# cyt4dn register map
Vendor: Cypress Semiconductor; Series: cyt4dn; File version: 1.0
CPU: CM7 r0p1, little endian, MPU, FPU, VTOR, 3 interrupt priority bits
Registers are 32-bit, read-write, reset 0x0 unless marked. A register's access mark holds for its fields unless they carry their own. Offsets are from the block's base; [hi:lo] are bit positions; lines under a group give offsets from that group; {n}, {i} and the like mark numbered series; 'fields as' and 'values as' point back to an identical list; <NAME> marks a mode.

## SMIF0 (part 2 of 2) — SMIF subsystem (bridge + 2 core SMIFs, OR no bridge and 1 core SMIF)
Base 0x40400000
{0x20000+0x10000*i} CORE[{i}] (i=0..1) group — Serial Memory Interface
  0x00 CTL reset 0x500000 — Control
    [31] ENABLED — SMIF core enable: '0': Disabled. All non-retention registers are reset to their default value when this SMIF core is disabled. When this SMIF core is disabled, the XIP accesses produce AHB-Lite bus errors and AXI error responses. '1': Enabled. Notes: - Before disabling or resetting this SMIF core, SW should ensure that this SMIF core is NOT busy (STATUS.BUSY is '0'), otherwise illegal interface transfers may occur. - After CTL.ENABLED is set to 1 it takes up to 20 clk_if cycles until the memory interface registers are realeased from reset. - The DLL is powered up when CTL.ENABLED is set to 1. It takes 8us for the DLL to stabilize and lock to the freerunning PLL clock at which point STATUS.DLL_LOCKED and INTR.DLL_LOCK will be set. Wait another 4us beyond that before executing any transactions on the memory interface; the MDL and SDLs require that extra time after the lock indication to reach their final stable delay values.
      0=DISABLED (N/A); 1=ENABLED (N/A)
    [25] CLOCK_IF_SEL — Specifies the clock source for 'clk_if'. Must be 0 (clk_pll_normal) before entering DeepSleep; can be returned to 1 (clk_pll_direct) afterwards. '0': clk_pll_normal is used to create clk_if '1': clk_pll_direct is used to create clk_if
    [24] BLOCK — Specifies what happens for MMIO interface read accesses to an empty RX data FIFO or to a full TX format/data FIFO. This field is not used for test controller accesses.
      0=BUS_ERROR (0': Generate an AHB-Lite bus error. This option is useful when SW decides to use polling on STATUS.TR_BUSY to determine if a interface transfer is no longer busy (transfer is completed). This option adds SW complexity, but limits the number of AHB-Lite wait states (and limits ISR latency).); 1=WAIT_STATES (1': Introduce wait states. This setting potentially locks up the AHB-Lite infrastructure and may increase the CPU interrupt latency.This option is useful when SW performs TX/RX data FIFO accesses immediately after a command is setup using the TX format FIFO. This option has low SW complexity, but may result in a significant number of AHB-Lite wait states (and may increase ISR latency). This can be particularly true if ARB_MODE=1 and an MMIO access must wait a potentially long time behind a XIP access.)
    [23:22] SELECT_HOLD_DELAY — Specifies the duration between the last 'spi_clk_out' falling edge and 'spi_select_out[]' deactivating (going high) before considering any MDL delay due to CTL2.MDL_TAP_SEL. Add that delay to the below values, plus allow some margin for combinatorial variances between spi_select_out[] and spi_clk_out. i.e., if after adding the MDL delay the timing would barely meet the memory datasheet requirement then it is recommended to go to the next higher setting. These values apply for DDR mode, or SDR mode with CTL2.TX_SDR_EXTRA_SETUP=0. For SDR mode with CTL2.TX_SDR_EXTRA_SETUP=1 subtract 1 PLL clock cycle from these values. DDR or SDR mode is determined by the mode of the last phase of the transaction. '0': 1 memory interface clock cycle + CTL2.CLKOUT_DIV adjustment '1': 2 memory interface clock cycles + CTL2.CLKOUT_DIV adjustment '2': 3 memory interface clock cycles + CTL2.CLKOUT_DIV adjustment '3': 4 memory interface clock cycles + CTL2.CLKOUT_DIV adjustment For the following settings of CTL2.CLKOUT_DIV apply these adjustments to the above: 0 (DIV2): subtract 1 PLL clock cycle 1 (DIV4): no adjustment needed 2 (DIV8): add 2 PLL clock cycles 3 (DIV16): add 6 PLL clock cycles
    [21:20] SELECT_SETUP_DELAY — Specifies the duration between 'spi_select_out[]' activating (going low) to the first 'spi_clk_out' rising edge before considering any MDL delay due to CTL2.MDL_TAP_SEL. Subtract that delay from the below values, plus allow some margin for combinatorial variances between spi_select_out[] and spi_clk_out. i.e., if after subtracting the MDL delay the timing would barely meet the memory datasheet requirement then it is recommended to go to the next higher setting. These values apply for DDR mode, or SDR mode with CTL2.TX_SDR_EXTRA_SETUP=0. For SDR mode with CTL2.TX_SDR_EXTRA_SETUP=1 add 1 PLL clock cycle to these values. DDR or SDR mode is determined by the mode of the first phase of the transaction. '0': 2 PLL clock cycles '1': 2 PLL clock cycles + 1 memory interface clock cycles '2': 2 PLL clock cycles + 2 memory interface clock cycles '3': 2 PLL clock cycles + 3 memory interface clock cycles
    [18:16] DESELECT_DELAY — Specifies the minimum duration of SPI deselection ('spi_select_out[]' is high/'1') in between SPI transfers: '0': 1 memory interface clock cycle. '1': 2 memory interface clock cycles. '2': 3 memory interface clock cycles. '3': 4 memory interface clock cycles. '4': 5 memory interface clock cycles. '5': 6 memory interface clock cycles. '6': 7 memory interface clock cycles. '7': 8 memory interface clock cycles. During SPI deselection, 'spi_select_out[]' are '1'/inactive, 'spi_data_out[]' are '1' and 'spi_clk_out' is '0'/inactive.
    [0] XIP_MODE — Mode of operation. Note: this field should only be changed when the IP is disabled or when STATUS.BUSY is '0' and SW should not be executing from the XIP interface or MMIO interface.
      0=MMIO_MODE ('0': MMIO mode. Individual MMIO accesses to TX and RX FIFOs are used to generate a sequence of SPI transfers. This mode of operation allows for large flexibility in terms of the SPI transfers that can be generated.); 1=ARB_MODE (''1': Arbitration mode. Arbitrates XIP vs. MMIO accesses such that any ongoing, pending, or 'merged' transactions on XIP always take priority over any MMIO accesses to the device. However, if an MMIO access is in process it cannot be interrupted until it completes (as defined by sending the 'last command' via TX_CMD_MMIO_FIFO_WR). If MMIO accesses are not happening at all, though, then the XIP accesses endure no extra arbitration latency.)
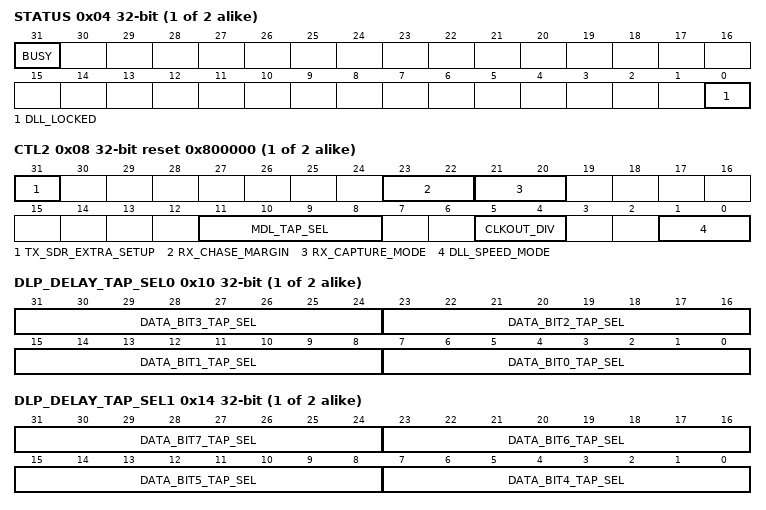
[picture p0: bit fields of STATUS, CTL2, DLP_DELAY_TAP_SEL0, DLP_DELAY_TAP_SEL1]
  0x04 STATUS ro reset not defined
    [31] BUSY — AHB Cache, AXI interface, cryptography, XIP, device interface, MPC (if present) initialization, or any other key logic busy in the IP: '0': not busy '1': busy When BUSY is '0', the IP can be safely disabled without: - the potential loss of transient write data. - the potential risk of aborting an inflight SPI device interface transfer. - disrupting MPC (if present) initialization When BUSY is '0', the mode of operation (ARB_MODE or MMIO_MODE) can be safely changed.
    [0] DLL_LOCKED — 0: DLL is not locked 1: DLL is locked Once the reference clock to the DLL is stable and the DLL is powered (CTL.ENABLED=1), the DLL should lock within 8us. The lock time will also be incurred when transitioning from DeepSleep to Active. Wait another 4us beyond the lock indication before executing any transactions on the memory interface; the MDL and SDLs require that extra time after the lock indication to reach their final stable delay values. If the DLL suddenly becomes unlocked then the TX interface will be held in reset to prevent any further transactions to the memory. The block should be disabled (CTL.ENABLED=0) to reset all other non-retention registers. Any data in the internal FIFOs will be lost. The DLL suddenly unlocking is considered an unusual event that would only occur if the reference clock to the DLL had a sudden change in frequency, which should only happen at the direction of SW. When transitioning to DeepSleep the DLL will naturally unlock. However, upon returning to Active all non-retention registers are reset and thus disabling the block to enact that reset is not necessary.
  0x08 CTL2 reset 0x800000 — Control 2
    [31] TX_SDR_EXTRA_SETUP — This field is only applicable in SDR transmit mode. 0: transmit data is launched nominally 1 PLL clock period ahead of the rising edge of the clock out to the memory 1: transmit data is launched nominally 2 PLL clock periods ahead of the rising edge of the clock out to the memory
    [23:22] RX_CHASE_MARGIN — Determines how long the design should wait after sending the last clock out to the memory interface before 'chase' clocks should be created internally to push remainder data in the interface pipeline into the RX FIFO. Lesser numbers allow for shorter deselect cycles between packets, but if the time is too short then the chase clocks will interfere with the normal capture clock from the last clock cycle from the memory interface (whether it is feedback or RWDS). So a proper balance must be struck. The default value is expected to work for all situations. Other values are there as a backup plan in case something more aggressive can be achieved or whether something even more conservative should be used.
    [21:20] RX_CAPTURE_MODE
    [11:8] MDL_TAP_SEL — Determines the relative amount of delay through the MDL for the reference clock in terms of the number of tap delays. There are 16 MDL taps that evenly divide the reference clock period into 16 delay steps. Setting 0 constitutes 1 tap delay, setting 1 constitutes 2 tap delays, etc., setting 15 constitutes 16 tap delays (which is effectively a full MDL reference clock period, which can be thought of as 'zero delay' since it aligns the posedges of the output to the input reference).
    [5:4] CLKOUT_DIV — The clock out to the memory is a divided version of the MDL clock out: 0: divide by 2 1: divide by 4 2: divide by 8 3: divide by 16
    [1:0] DLL_SPEED_MODE — Set according to the PLL clock frequency that feeds the DLL: 0: 160 to 180 MHz 1: >180 to 266 MHz 2: >266 to 333 MHz 3: >333 to 400 MHz
  0x10 DLP_DELAY_TAP_SEL0 ro reset not defined — DLP Delay Tap Select Register 0
    [31:24] DATA_BIT3_TAP_SEL — Delay line tap selection for the IP's spi_data[3] (note the mapping of spi_data to IO in DEVICE.CTL.DATA_SEL). See DATA_BIT0_TAP_SEL.
    [23:16] DATA_BIT2_TAP_SEL — Delay line tap selection for the IP's spi_data[2] (note the mapping of spi_data to IO in DEVICE.CTL.DATA_SEL). See DATA_BIT0_TAP_SEL.
    [15:8] DATA_BIT1_TAP_SEL — Delay line tap selection for the IP's spi_data[1] (note the mapping of spi_data to IO in DEVICE.CTL.DATA_SEL). See DATA_BIT0_TAP_SEL.
    [7:0] DATA_BIT0_TAP_SEL — DLP tap selection for the IP's spi_data[0] (note the mapping of spi_data to IO in DEVICE.CTL.DATA_SEL). In SDR mode: The upper 4 bits of this field are zero, while the lower 4 bits represent the winning tap selection for all received bits on this data line. In DDR mode: The upper 4 bits of this field represent the winning tap selection for the bits received in the MSB data of the DDR pair, while the lower 4 bits represent the winning tap selection for the bits received in the LSB data of the DDR pair on this data line. A 'winning tap selection' in either case is mapped as {tap15 of neg SDL, tap13 of neg SDL,..., tap1 of neg SDL, tap15 of pos SDL, tap13 of pos SDL,..., tap1 of pos SDL} for values 15 to 0, respectively.
  0x14 DLP_DELAY_TAP_SEL1 ro reset not defined — DLP Delay Tap Select Register 1
    [8n-25:8n-32] DATA_BIT{n}_TAP_SEL (n=4..7) — Delay line tap selection for the IP's spi_data[{n}] (note the mapping of spi_data to IO in DEVICE.CTL.DATA_SEL). See DATA_BIT0_TAP_SEL.
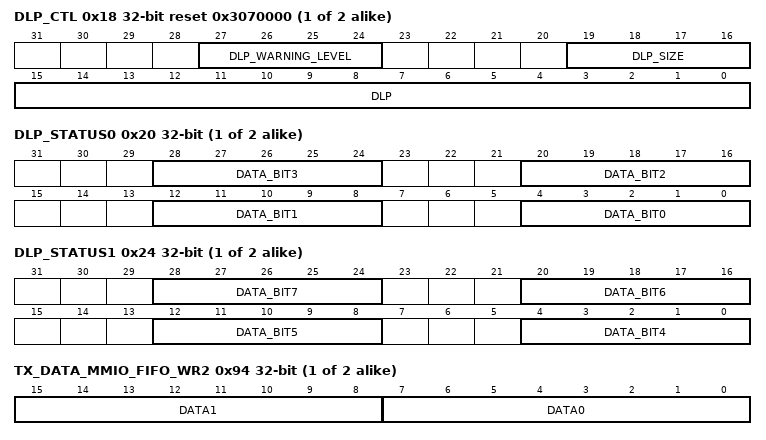
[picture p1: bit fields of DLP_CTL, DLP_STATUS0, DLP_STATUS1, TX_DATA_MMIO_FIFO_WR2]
  0x18 DLP_CTL reset 0x3070000 — DLP Control Register
    [27:24] DLP_WARNING_LEVEL — Determines when the DLP_WARNING interrupt cause field is set: - DLP_WARNING is set when the number of delay line taps resulting to a correctly captured DLP is less than DLP_WARNING_LEVEL for at least one input data line Note: To provide a margin in both directions relatively to the selected middle tap at least 3 delay line taps have to result into a correctly captured DLP, i.e. the DLP_WARNING_LEVEL has to be set to greater or equal 3.
    [19:16] DLP_SIZE — Size of data learning pattern as such: '0': 1 bit ... '15': 16 bit. If CTL2.RX_CAPTURE_MODE=1 then the DLP_SIZE+1 LSBs of the expected data learning pattern (DLP[DLP_SIZE:0]) are compared with the data learning pattern generated by the memory device and captured during the last latency / dummy cycles of a memory read transfer. Note: For DDR read data transfers the size of the DLP must be an even number, i.e. DLP_SIZE must be an odd number.
    [15:0] DLP — Data Learning Pattern
  0x20 DLP_STATUS0 ro reset not defined — DLP Status Register 0
    [28:24] DATA_BIT3 — Same as the DATA_BIT0 description except for spi_data[3]
    [20:16] DATA_BIT2 — Same as the DATA_BIT0 description except for spi_data[2]
    [12:8] DATA_BIT1 — Same as the DATA_BIT0 description except for spi_data[1]
    [4:0] DATA_BIT0 — In SDR mode: Number of delay line taps for the IP's spi_data[0] (note the mapping of spi_data to IO in DEVICE.CTL.DATA_SEL) with correctly captured DLP in last read transaction. Legal values: 0 to 16. In DDR mode: Similar to SDR except the MSB and LSB data of the DDR pair are evaluated separately and this field reflects the least number of successful taps between those two evaluations.
  0x24 DLP_STATUS1 ro reset not defined — DLP Status Register 1
    [8n-28:8n-32] DATA_BIT{n} (n=4..7) — Same as the DATA_BIT0 description except for spi_data[{n}]
  0x44 TX_CMD_FIFO_STATUS ro — Transmitter command FIFO status
    [3:0] USED4 — Number of entries that are used in the TX command FIFO. Legal range: [0, 8].
  0x48 TX_CMD_MMIO_FIFO_STATUS ro — Transmitter command MMIO FIFO status
    [3:0] USED4 — Number of entries that are used in the TX command MMIO FIFO. Legal range: [0, 8].
  0x50 TX_CMD_MMIO_FIFO_WR wo — Transmitter command MMIO FIFO write
    [26:0] DATA27
  0x80 TX_DATA_MMIO_FIFO_CTL — Transmitter data MMIO FIFO control
    [2:0] TX_TRIGGER_LEVEL — Determines when the TX data MMIO FIFO 'tr_tx_req' trigger is activated: - Trigger is active when TX_DATA_MMIO FIFO_STATUS.USED <= TRIGGER_LEVEL.
  0x84 TX_DATA_FIFO_STATUS ro — Transmitter data FIFO status
    [3:0] USED4 — Number of entries that are used in the TX data FIFO. Legal range: [0, 8].
  0x88 TX_DATA_MMIO_FIFO_STATUS ro — Transmitter data MMIO FIFO status
    [3:0] USED4 — Number of entries that are used in the TX data MMIO FIFO. Legal range: [0, 8].
  0x90 TX_DATA_MMIO_FIFO_WR1 wo — Transmitter data MMIO FIFO write
    [7:0] DATA0 — TX data (written to TX data MMIO FIFO).
  0x94 TX_DATA_MMIO_FIFO_WR2 wo — Transmitter data MMIO FIFO write
    [15:8] DATA1 — TX data (written to TX data MMIO FIFO, second byte).
    [7:0] DATA0 — TX data (written to TX data MMIO FIFO, first byte).
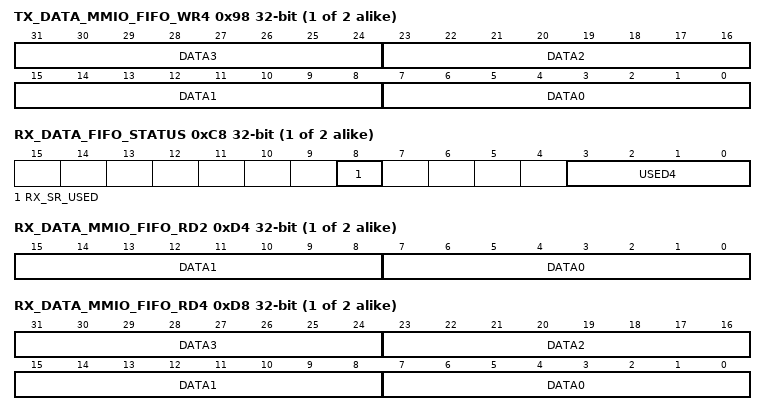
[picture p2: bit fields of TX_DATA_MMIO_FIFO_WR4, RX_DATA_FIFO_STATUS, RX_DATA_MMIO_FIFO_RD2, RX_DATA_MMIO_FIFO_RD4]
  0x98 TX_DATA_MMIO_FIFO_WR4 wo — Transmitter data MMIO FIFO write
    [31:24] DATA3 — TX data (written to TX data MMIO FIFO, fourth byte).
    [23:16] DATA2 — TX data (written to TX data MMIO FIFO, third byte).
    [15:8] DATA1 — TX data (written to TX data MMIO FIFO, second byte).
    [7:0] DATA0 — TX data (written to TX data MMIO FIFO, first byte).
  0x9C TX_DATA_MMIO_FIFO_WR1ODD wo — Transmitter data MMIO FIFO write
    [7:0] DATA0 — TX data (written to TX data MMIO FIFO).
  0xC0 RX_DATA_MMIO_FIFO_CTL — Receiver data MMIO FIFO control
    [2:0] RX_TRIGGER_LEVEL — Determines when RX data FIFO 'tr_rx_req' trigger is activated: - Trigger is active when RX_DATA_MMIO_FIFO_STATUS.USED > TRIGGER_LEVEL.
  0xC4 RX_DATA_MMIO_FIFO_STATUS ro — Receiver data MMIO FIFO status
    [3:0] USED4 — Number of entries that are used in the RX data MMIO FIFO. Legal range: [0, 8].
  0xC8 RX_DATA_FIFO_STATUS ro — Receiver data FIFO status
    [8] RX_SR_USED — Data available in RX Shift Register, i.e. completely read from RX data FIFO.
    [3:0] USED4 — Number of entries that are used in the RX data FIFO. Legal range: [0, 8].
  0xD0 RX_DATA_MMIO_FIFO_RD1 ro — Receiver data MMIO FIFO read
    [7:0] DATA0 — RX data (read from RX data FIFO).
  0xD4 RX_DATA_MMIO_FIFO_RD2 ro — Receiver data MMIO FIFO read
    [15:8] DATA1 — RX data (read from RX data FIFO, second byte).
    [7:0] DATA0 — RX data (read from RX data FIFO, first byte).
  0xD8 RX_DATA_MMIO_FIFO_RD4 ro — Receiver data MMIO FIFO read
    [31:24] DATA3 — RX data (read from RX data FIFO, fourth byte).
    [23:16] DATA2 — RX data (read from RX data FIFO, third byte).
    [15:8] DATA1 — RX data (read from RX data FIFO, second byte).
    [7:0] DATA0 — RX data (read from RX data FIFO, first byte).
  0xE0 RX_DATA_MMIO_FIFO_RD1_SILENT ro — Receiver data MMIO FIFO silent read
    [7:0] DATA0 — RX data (read from RX data FIFO).
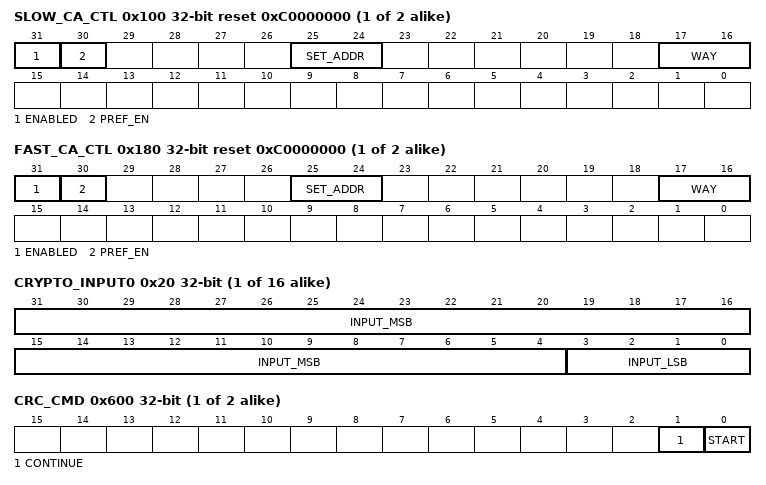
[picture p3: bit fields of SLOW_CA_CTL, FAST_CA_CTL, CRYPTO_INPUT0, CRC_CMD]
  0x100 SLOW_CA_CTL reset 0xC0000000 — Slow cache control
    [31] ENABLED — Cache enable: '0': Disabled. '1': Enabled.
    [30] PREF_EN — Prefetch enable: '0': Disabled. '1': Enabled. Prefetching requires the cache to be enabled; i.e. ENABLED is '1'.
    [25:24] SET_ADDR — Specifies the cache set for which cache information is provided in SLOW_CA_STATUS0/1/2.
    [17:16] WAY — Specifies the cache way for which cache information is provided in SLOW_CA_STATUS0/1/2.
  0x108 SLOW_CA_CMD — Slow cache command
    [0] INV — Cache and prefetch buffer invalidation. SW writes a '1' to clear the cache and prefetch buffer. The cache's LRU structure is also reset to its default state. Note, A write access will invalidate the prefetch buffer automatically in hardware. A write access should invalidate both fast and slow caches, by firmware. Note, firmware should invalidate the cache and prefetch buffer only when STATUS.BUSY is '0'.
  0x180 FAST_CA_CTL reset 0xC0000000 — Fast cache control
    [31] ENABLED — See SLOW_CA_CTL.ENABLED.
    [30] PREF_EN — See SLOW_CA_CTL.PREF_EN.
    [25:24] SET_ADDR — See SLOW_CA_CTL.SET_ADDR.
    [17:16] WAY — See SLOW_CA_CTL.WAY.
  0x188 FAST_CA_CMD — Fast cache command
    [0] INV — See SLOW_CA_CMD.INV.
  {0x200+0x80*j} SMIF_CRYPTO[{j}] (j=0..7) group — Cryptography registers (one set for each key)
    0x00 CRYPTO_CMD — Cryptography command
      [0] START — SW sets this field to '1' to start an AES-128 forward block cipher operation (on CRYPTO_INPUT0-3). HW sets this field to '0' to indicate that the operation has completed. Once completed, the result of the operation can be read from CRYPTO_OUTPUT0, ..., CRYPTO_OUTPUT3. The operation takes roughly 13 clk_mem clock cycles. This register is only applicable for MMIO accesses and only in MMIO_MODE. XIP accesses are encrypted on-the-fly in ARB_MODE and thus do not use this register. Because XIP has exclusive access to the crypto engine in ARB_MODE, MMIO encryption is not available in that mode. As such if encryption is needed for MMIO accesses in ARB_MODE that encryption must be done by other means (i.e., chip level crypto).
    0x04 CRYPTO_ADDR — Cryptography base address
      [31:8] ADDR — Only applies to XIP accesses. Specifies the base address of the memory region that will have cryptography applied on XIP accesses with a unique key. If this region overlaps with another key's region, the lower numbered key is used (i.e., crypto key 0 has the highest priority). If the region is 2^m Bytes, ADDR MUST be a multiple of 2^m. The most significant bit fields are constants and set based on the SMIF_XIP_ADDR parameter. The most significant bits are identified on the SMIF_XIP_MASK parameter. E.g., if SMIF_XIP_MASK is 0xff00:0000 (16 MB XIP memory region), ADDR[31:24] = SMIF_XIP_ADDR[31:24]. Note that in order for cryptogrpahy to be applied the DEVICE.CTL.CRYPTO_EN must be set to 1 as well for any devices that share this region.
    0x08 CRYPTO_MASK — Cryptography mask
      [31:8] MASK — Only applies to XIP accesses. Specifies the size of the memory region whose base address is determined by CRYPTO_ADDR. All '1' bits are used to compare the incoming transfer request address A[31:0] with the address as specified in CRYPTO_ADDR.ADDR: Address A is in the cryptography region when (A[31:8] & MASK[31:8]) == CRYPTO_ADDR.ADDR[31:8]. The most significant bit fields are constants and set to'1'. The most significant bits are identified on the SMIF_XIP_MASK parameter. E.g., if SMIF_XIP_MASK is 0xff00:0000 (16 MB XIP memory region), MASK[31:24] = 0xff.
    0x0C CRYPTO_SUBREGION — Cryptography subregion disable
      [7:0] SUBREGION_DISABLE — Only applies to XIP accesses. The cryptography region for this key as determined by CRYPTO_ADDR and CRYPTO_MASK is further divided into 8 equal subregions. e.g., if a 1 MB region is specified then the 8 subregions will be 128 KB. If SUBREGION_DISABLE=0 then cryptography will be performed on that subregion (assuming any associated DEVICE.CTL.CRYPTO_EN=1). Otherwise if SUBREGION_DISABLE=1 then cryptography is not applied. Note that setting all SUBREGION_DISABLE bits to 1 will effectively disable this key. The encryption decision and the associated key are locked in at the beginning of a memory access and will apply until the end of such atomic accesses. Therefore, it is the user's responsibility to ensure memory accesses do not span across (sub)regions that have different keys and/or cypto enabled/disabled differently across such (sub)regions.
    0x20 CRYPTO_INPUT0 reset not defined — Cryptography input 0
      [31:4] INPUT_MSB — Plaintext PT[31:4] = CRYPTO_INPUT0.INPUT_MSB.
      [3:0] INPUT_LSB — Plaintext PT[3:0] = CRYPTO_INPUT0.INPUT_LSB.
    {0x20+4k} CRYPTO_INPUT{k} reset not defined (k=1..3) — Cryptography input {k}
      [31:0] INPUT — Plaintext PT[{32k+31}:{32k}] = CRYPTO_INPUT{k}.INPUT[31:0].
    {0x40+4k} CRYPTO_KEY{k} wo reset not defined (k=0..3) — Cryptography key {k}
      [31:0] KEY — Four Bytes of the key KEY[{32k+31}:{32k}] = CRYPTO_KEY{k}.KEY[31:0].
    {0x60+4k} CRYPTO_OUTPUT{k} reset not defined (k=0..3) — Cryptography output {k}
      [31:0] OUTPUT — Four Bytes of the ciphertext CT[{32k+31}:{32k}] = CRYPTO_OUTPUT{k}.OUTPUT[31:0].
  0x600 CRC_CMD — CRC Command
    [1] CONTINUE — SW sets this field to '1' to continue a CRC calculation over the 64 CRC input bits provided in CRC_INPUT0 and CRC_INPUT1, using the current CRC output in CRC_OUTPUT as CRC feedback. HW sets this field to '0' to indicate that the operation has completed. Once completed, the result of the operation can be read from CRC_OUTPUT. This command is used to perform a CRC calculation over more than 64 intput bits. For example a CRC calculation over 128 bits is done by writing the first 64 input bits to CRC_INPUT0/1, performing a START command, writing the second 64 input bits to CRC_INPUT0/1, performing a CONTINUE command and reading the CRC result from CRC_OUTPUT. For a CRC calculation of even more input bits the CONTINUE command has to be used multiple times. This register is only applicable for MMIO accesses.
    [0] START — SW sets this field to '1' to start a CRC calculation over the 64 CRC input bits provided in CRC_INPUT0 and CRC_INPUT1, using 0xFF as CRC feedback. HW sets this field to '0' to indicate that the operation has completed. Once completed, the result of the operation can be read from CRC_OUTPUT. A CRC calculation over 64 bits is done by writing the 64 input bits to CRC_INPUT0/1, performing a START command and reading the CRC result from CRC_OUTPUT. This register is only applicable for MMIO accesses.
  0x620 CRC_INPUT0 reset not defined
    [31:0] INPUT — Lower 32 input bits to the CRC engine.
  0x624 CRC_INPUT1 reset not defined
    [31:0] INPUT — Higher 32 input bits to the CRC engine.
  0x640 CRC_OUTPUT ro reset 0xFF
    [7:0] CRC_OUTPUT — CRC engine output.
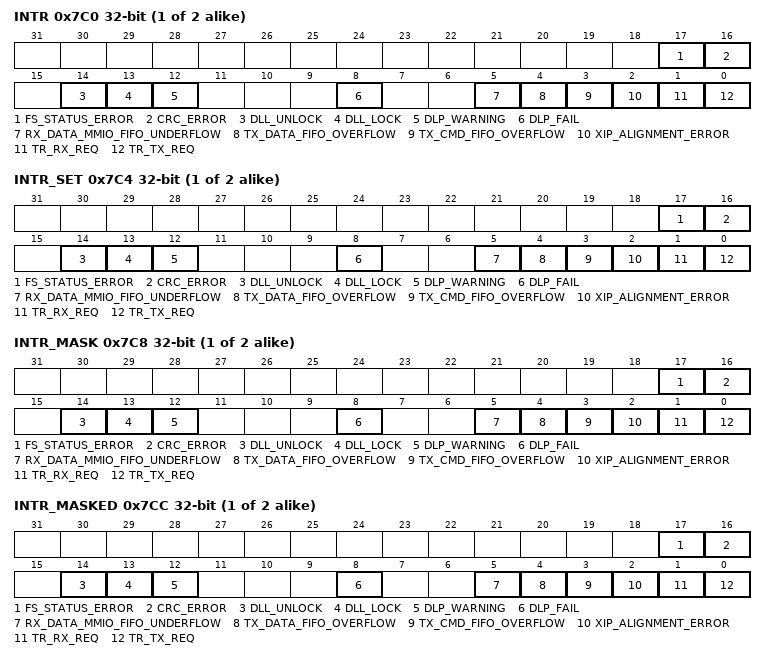
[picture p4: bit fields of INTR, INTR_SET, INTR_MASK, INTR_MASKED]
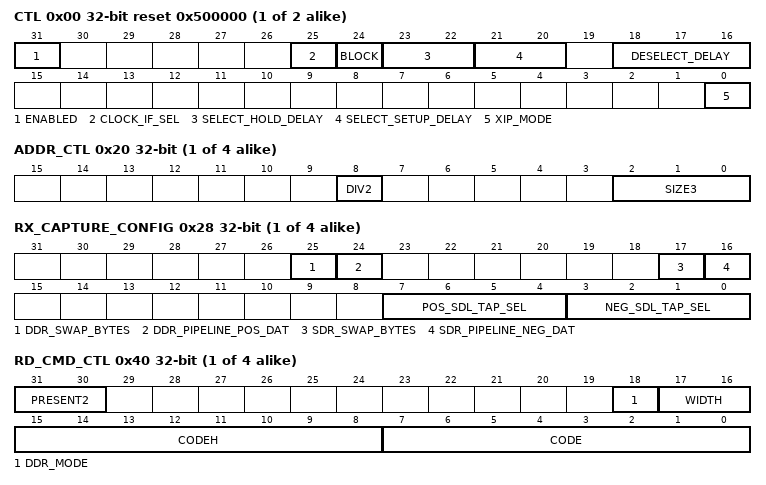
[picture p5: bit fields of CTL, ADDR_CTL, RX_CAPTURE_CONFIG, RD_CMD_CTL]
  0x7C0 INTR — Interrupt register
    [17] FS_STATUS_ERROR — Functional Safety Status Error. A read transfer Functional Safety Status check failed (see definition in DEVICE_ver2.RD_CRC_CTL.STATUS_CHECK_MASK and DEVICE_ver2.RD_CRC_CTL.STATUS_CHECK_MASK_POL).
    [16] CRC_ERROR — CRC Error. A read transfer data CRC check failed.
    [14] DLL_UNLOCK — DLL unlock (edge detected)
    [13] DLL_LOCK — DLL lock (edge detected)
    [12] DLP_WARNING — Data Learning Warning (for at least one input data line less then DLP.DLP_WARNING_LEVEL delay line taps resulted in a correct DLP capturing when CTL2.RX_CAPTURE_MODE=1). This interrupt will be suppressed, though, if DLP_FAIL also occurs during the same DLP evaluation cycle.
    [8] DLP_FAIL — Data Learning Failed (no DLP match found on at least one of the input data lines when CTL2.RX_CAPTURE_MODE=1).
    [5] RX_DATA_MMIO_FIFO_UNDERFLOW — Activated on an AHB-Lite read transfer from the RX data MMIO FIFO (RX_DATA_MMIO_FIFO_RD1, RX_DATA_MMIO_FIFO_RD2, RX_DATA_MMIO_FIFO_RD4) with not enough entries available. Only activated for NON test bus controller transfers.
    [4] TX_DATA_FIFO_OVERFLOW — Activated on an AHB-Lite write transfer to the TX data MMIO FIFO (TX_DATA_MMIO_FIFO_WR1, TX_DATA_MMIO_FIFO_WR2, TX_DATA_MMIO_FIFO_WR4, TX_DATA_MMIO_FIFO_WR1ODD) with not enough free entries available.
    [3] TX_CMD_FIFO_OVERFLOW — Activated on an AHB-Lite write transfer to the TX command MMIO FIFO (TX_CMD_MMIO_FIFO_WR) with not enough free entries available.
    [2] XIP_ALIGNMENT_ERROR — Activated on a XIP access, when: - a write transfer is requested and - Dual-Quad SPI mode (selected device's ADDR_CTL.DIV2 is '1') is selected or - Octal SPI DDR mode (selected device's DATA_CTL.DDR_MODE = '1' and DATA_CTL.WIDTH = '3') or Hyperbus mode (selected device's ADDR_CTL.SIZE3 = '7') is selected without memory write byte masking (selected device's WR_DUMMY_CTL.RWDS_EN = '0') and - the AHB-Lite / AXI bus transfer address is not a multiple of '2' or - the requested AHB-Lite / AXI bus transfer size is NOT a multiple of '2'. Additionally, it is activated on a XIP access when the selected memory device does not support write byte masking (WR_DUMMY_CTL.RWDS_EN=0) and an AXI transfer occurs with not all of the AXI write strobes ('wstrb') enabled according to the transfer size ('assize'). Note: In dual-quad SPI mode (ADDR_CTL.DIV is '1'), each memory device contributes a 4-bit nibble for read data or write data. Write accesses are only possible if the request address is a multiple of 2 and the number of requested Bytes is a multiple of 2. Octal SPI DDR mode or Hyperbus mode are 16-bit word based protocols, writing single bytes is only possible when write byte masking is supported (via RWDS). Read accesses are always possible by extending the transfer size and / or aligning the address as needed and discarding the non-relevant byte(s).
    [1] TR_RX_REQ — Activated when a RX data MMIO FIFO trigger 'tr_rx_req' is activated.
    [0] TR_TX_REQ — Activated when a TX data MMIO FIFO trigger 'tr_tx_req' is activated.
  0x7C4 INTR_SET — Interrupt set register
    [17] FS_STATUS_ERROR — Write with '1' to set corresponding bit in interrupt request register.
    [16] CRC_ERROR — Write with '1' to set corresponding bit in interrupt request register.
    [14] DLL_UNLOCK — Write with '1' to set corresponding bit in interrupt request register.
    [13] DLL_LOCK — Write with '1' to set corresponding bit in interrupt request register.
    [12] DLP_WARNING — Write with '1' to set corresponding bit in interrupt request register.
    [8] DLP_FAIL — Write with '1' to set corresponding bit in interrupt request register.
    [5] RX_DATA_MMIO_FIFO_UNDERFLOW — Write with '1' to set corresponding bit in interrupt request register.
    [4] TX_DATA_FIFO_OVERFLOW — Write with '1' to set corresponding bit in interrupt request register.
    [3] TX_CMD_FIFO_OVERFLOW — Write with '1' to set corresponding bit in interrupt request register.
    [2] XIP_ALIGNMENT_ERROR — Write with '1' to set corresponding bit in interrupt request register.
    [1] TR_RX_REQ — Write with '1' to set corresponding bit in interrupt request register.
    [0] TR_TX_REQ — Write with '1' to set corresponding bit in interrupt request register.
  0x7C8 INTR_MASK — Interrupt mask register
    [17] FS_STATUS_ERROR — Mask bit for corresponding bit in interrupt request register.
    [16] CRC_ERROR — Mask bit for corresponding bit in interrupt request register.
    [14] DLL_UNLOCK — Mask bit for corresponding bit in interrupt request register.
    [13] DLL_LOCK — Mask bit for corresponding bit in interrupt request register.
    [12] DLP_WARNING — Mask bit for corresponding bit in interrupt request register.
    [8] DLP_FAIL — Mask bit for corresponding bit in interrupt request register.
    [5] RX_DATA_MMIO_FIFO_UNDERFLOW — Mask bit for corresponding bit in interrupt request register.
    [4] TX_DATA_FIFO_OVERFLOW — Mask bit for corresponding bit in interrupt request register.
    [3] TX_CMD_FIFO_OVERFLOW — Mask bit for corresponding bit in interrupt request register.
    [2] XIP_ALIGNMENT_ERROR — Mask bit for corresponding bit in interrupt request register.
    [1] TR_RX_REQ — Mask bit for corresponding bit in interrupt request register.
    [0] TR_TX_REQ — Mask bit for corresponding bit in interrupt request register.
  0x7CC INTR_MASKED ro — Interrupt masked register
    [17] FS_STATUS_ERROR — Logical and of corresponding request and mask bits.
    [16] CRC_ERROR — Logical and of corresponding request and mask bits.
    [14] DLL_UNLOCK — Logical and of corresponding request and mask bits.
    [13] DLL_LOCK — Logical and of corresponding request and mask bits.
    [12] DLP_WARNING — Logical and of corresponding request and mask bits.
    [8] DLP_FAIL — Logical and of corresponding request and mask bits.
    [5] RX_DATA_MMIO_FIFO_UNDERFLOW — Logical and of corresponding request and mask bits.
    [4] TX_DATA_FIFO_OVERFLOW — Logical and of corresponding request and mask bits.
    [3] TX_CMD_FIFO_OVERFLOW — Logical and of corresponding request and mask bits.
    [2] XIP_ALIGNMENT_ERROR — Logical and of corresponding request and mask bits.
    [1] TR_RX_REQ — Logical and of corresponding request and mask bits.
    [0] TR_TX_REQ — Logical and of corresponding request and mask bits.
  {0x800+0x80*j} DEVICE[{j}] (j=0..1) group — Device (only used for XIP acceses)
    0x00 CTL — Control
      [31] ENABLED — Device enable: '0': Disabled. '1': Enabled.
      [30] TOTAL_TIMEOUT_EN — Total transfer timeout enable. '0': Disabled. There is no limit for the total transfer time. The continuous transfer merge timeout for limiting the idle time of the memory interface still applies. '1': Enabled. The maximum total transfer time is limited by field TOTAL_TIMEOUT.
      [29:16] TOTAL_TIMEOUT — Total transfer timeout in clk_mem cycles. The counting of the total timout period is done in the XIP block using clk_mem cycles. It starts when the first command of a new (not merged) transaction is transferred to the TX command FIFO causing the interface logic to select the memory. After this period the memory device is deselected. This feature is needed for RAM devices requiring refresh cycles. The value needs to be derived from the RAMs maximum transaction length time (tCMS) minus the time of transferring 2x16byte data block (data granularity of the XIP ports is 16byte, 1 16byte block transfer outstanding, another available for merging). If the result in negative, MERGE_EN must be set to '0'. Example: RAM device tCMS = 4us, interface clock frequency = 100MHz: total transfer timeout is 4us - 2x16x10ns = 3680ns. With clk_mem frequency of 200MHz the TOTAL_TIMEOUT value is 3680/5 = 736. Note: In the unlikely case that the total transfer timeout is used (usually for RAM devices) while the page boundary crossing latency generation is enabled via RD_BOUND_CTL.PRESENT (usually for FLASH devices) the additional time needs to taken into account.
      [15] MERGE_EN — Continous transfer merge enable: '0': Disabled. No merging of transfers is done. Longest possible memory transfer is 16 Byte. '1': Enabled. Merging of continous transfers is done. This skips the overhead (command, address, mode, dummy cycles) for a continuous (linear sequential) transfer.
      [14:12] MERGE_TIMEOUT — Continuous transfer merge timeout in clk_mem cycles. This limits the standby time of the memory interface, i.e. the time the memory device is selected but no data is transferred. The counting of the merge timeout period is done in the XIP block using clk_mem cycles. It starts when the last TX or RX byte is transferred to or from the data FIFOs. After this period the memory device is deselected. A later transfer, even from a continuous address, starts with the overhead phases (command, address, mode, dummy cycles).
        0=_1_cycle (Timeout after 1 clk_mem cycle. That means transfers will only be merged if the continuous transfer request is already available when the previous transfer is finished.); 1=_16_cycles (Timeout after 2^4 = 16 clk_mem cycles. At a clk_mem frequency of 200MHz this means 80ns.); 2=_256_cycles (Timeout after 2^8 = 256 clk_mem cycles. At a clk_mem frequency of 200MHz this means ~1.3us.); 3=_4096_cycles (Timeout after 2^12 = 4096 clk_mem cycles. At a clk_mem frequency of 200MHz this means ~20us.); 4=_65536_cycles (Timeout after 2^16 = 65536 clk_mem cycles. At a clk_mem frequency of 200MHz this means ~330us.); 5=RSVD5 (N/A); 6=RSVD6 (N/A); 7=RSVD7 (N/A)
      [9:8] DATA_SEL — Specifies the connection of the IP's data lines (spi_data[0], ..., spi_data[7]) to the device's data lines (SI/IO0, SO/IO1, IO2, IO3, IO4, IO5, IO6, IO7): '0': spi_data[0] = IO0, spi_data[1] = IO1, ..., spi_data[7] = IO7. This value is allowed for single, dual, quad, dual quad and octal SPI modes. This value must be used for the first device in dual quad SPI mode. This value must be used for octal SPI mode. '1': spi_data[2] = IO0, spi_data[3] = IO1. This value is only allowed for single and dual SPI modes. '2': spi_data[4] = IO0, spi_data[5] = IO1, ..., spi_data[7] = IO3. This value is only allowed for single, dual, quad and dual quad SPI modes. In dual quad SPI mode, this value must be used for the second device. '3': spi_data[6] = IO0, spi_data[7] = IO1. This value is only allowed for single and dual SPI modes.
      [4] CRYPTO_EN — Cryptography on read/write accesses: '0': disabled. '1': enabled.
      [0] WR_EN — Write enable: '0': write transfers are not allowed to this device. An attempt to write to this device results in an AHB-Lite bus error. '1': write transfers are allowed to this device.
    0x08 ADDR reset not defined — Device region base address
      [31:8] ADDR — Specifies the base address of the device region. If the device region is 2^m Bytes, ADDR MUST be a multiple of 2^m. In dual quad SPI data transfer, the two devices should have the same ADDR and MASK register settings. The device control information (ADDR_CTL, RD_CMD_CTL, etc.) are provided by the MMIO control registers of the device with the lowest index. The most significant bit fields are constants and set based on the SMIF_XIP_ADDR parameter. The most significant bits are identified on the SMIF_XIP_MASK parameter. E.g., if SMIF_XIP_MASK is 0xff00:0000 (16 MB XIP memory region), ADDR[31:24] = SMIF_XIP_ADDR[31:24].
    0x0C MASK reset not defined — Device region mask
      [31:8] MASK — Specifies the size of the device region. All '1' bits are used to compare the incoming transfer request address A[31:0] with the address as specified in ADDR.ADDR: Address A is in the device when (A[31:8] & MASK[31:8]) == ADDR.ADDR[31:8]. The most significant bit fields are constants and set to'1'. The most significant bits are identified on the SMIF_XIP_MASK parameter. E.g., if SMIF_XIP_MASK is 0xff00:0000 (16 MB XIP memory region), MASK[31:24] = 0xff. Note: a transfer request that is not in any device region results in an AHB-Lite bus error.
    0x20 ADDR_CTL — Address control
      [8] DIV2 — Specifies if the AHB-Lite bus transfer address is divided by 2 or not: '0': No divide by 2. '1': Divide by 2. This functionality is used for read and write operation in XIP, dual quad SPI mode; i.e. this DIV2 must be set to '1' in dual quad SPI mode. If DIV2 is set to '1', the memory does not support write masking (WR_DUMMY_CTL.RWDS_EN = '0'), and in this configuration a write transfer is requested and the write transfer request address is NOT a multiple of 2 or the requested number of Bytes to be written is not a multiple of 2, the XIP_ALIGNMENT_ERROR interrupt cause is activated.
      [2:0] SIZE3
    0x28 RX_CAPTURE_CONFIG — RX capture configuration
      [25] DDR_SWAP_BYTES — 0: Does not swap DDR receive data captured relative to the negedge of the receive clock with the data captured relative to the posedge of the receive clock 1: Does swap
      [24] DDR_PIPELINE_POS_DAT — 0: Does not pipeline DDR receive data captured relative to the posedge of the receive clock 1: Does pipeline
      [17] SDR_SWAP_BYTES — 0: Does not swap SDR receive data captured relative to the negedge of the receive clock with the data captured relative to the posedge of the receive clock 1: Does swap
      [16] SDR_PIPELINE_NEG_DAT — 0: Does not pipeline SDR receive data captured relative to the negedge of the receive clock 1: Does pipeline
      [7:4] POS_SDL_TAP_SEL — Same as NEG_SDL_TAP_SEL except for the 'pos' SDL.
      [3:0] NEG_SDL_TAP_SEL — Determines the amount of delay through the 'neg' SDL for the receive clock coming from the pins in terms of the number of tap delays. There are 16 SDL taps and the delay resolution of each tap is controlled by and thus closely mimics the delay resolution of the MDL. i.e., each tap has a resolution roughly equal to 1/16th of the DLL reference clock period. Setting 0 constitutes 1 tap delay, setting 1 constitutes 2 tap delays, etc., setting 15 constitutes 16 tap delays (effectively a full DLL reference clock period).
    0x30 RD_STATUS ro — Read status
      [7:0] FS_STATUS — Provides the Functional Safety Status Register of the memory received with the last read transfer.
    0x40 RD_CMD_CTL — Read command control
      [31:30] PRESENT2 — Presence of command field: '0': not present '1': present (1 Byte) '2': present (2 Byte for OPI) Note: For octal data transfer with DDR mode (WIDTH='3' and DDR_MODE='1') either the HB protocol needs to be selected (by ADDR_CTL.SIZE3='7') or this field needs to be set to PRESENT2='2'.
      [18] DDR_MODE — Mode of transfer rate: '0': SDR mode '1': DDR mode
      [17:16] WIDTH — Width of data transfer: '0': 1 bit/cycle (single data transfer). '1': 2 bits/cycle (dual data transfer). '2': 4 bits/cycle (quad data transfer). '3': 8 bits/cycle (octal data transfer).
      [15:8] CODEH — Command high byte code. This field specifies the most significant command byte, sent before the least significant command byte (CODE). It is only used when PRESENT2 = '2'.
      [7:0] CODE — Command byte code.
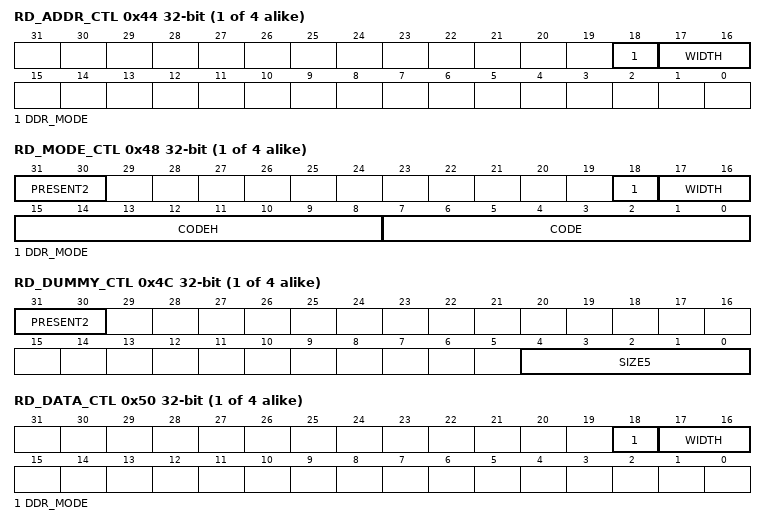
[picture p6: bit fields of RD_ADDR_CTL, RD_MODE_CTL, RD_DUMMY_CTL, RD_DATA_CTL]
    0x44 RD_ADDR_CTL — Read address control
      [18] DDR_MODE — Mode of transfer rate.
      [17:16] WIDTH — Width of transfer.
    0x48 RD_MODE_CTL — Read mode control
      [31:30] PRESENT2 — Presence of mode field: '0': not present '1': present (1 Byte) '2': present (2 Byte for OPI) Note: For octal data transfer with DDR mode (WIDTH='3' and DDR_MODE='1') this field needs to be set to PRESENT2='2' to generate a mode field (or to PRESENT2='0').
      [18] DDR_MODE — Mode of transfer rate.
      [17:16] WIDTH — Width of transfer.
      [15:8] CODEH — Mode high byte code. This field specifies the most significant mode byte, sent before the least significant mode byte (CODE). It is only used when PRESENT2 = '2'.
      [7:0] CODE — Mode byte code. Note: If a mode field is present (PRESENT='1') for octal data transfer with DDR mode (WIDTH='3' and DDR_MODE='1') the CODE is sent twice.
    0x4C RD_DUMMY_CTL — Read dummy control
      [31:30] PRESENT2 — Presence of dummy cycles: '0': not present '1': present '2': present - Dummy cycles are doubled when RWDS refresh indicator is high during CA cycle. (HyperRAM variable latency mode) Notes: - If transmitting command, address and mode fields in SDR mode (driving data between falling edges of spihb_clk_out) and the memory is driving read data in DDR mode (based on memory type and transmitted command), then there must be at least 1 latency / dummy cycle specified (RD_DUMMY_CTL.PRESENT2 > 0') to prevent controller and memory driving data signals at the same time. The same is true for the theoretical (practically irrelevant case) of transmitting at least one of the command, address and mode fields in DDR mode but receiving data from the memory in SDR mode. - When using the RWDS / DQS based capturing scheme (CTL.CLK_IF_RX_SEL=[6,7]), then there is a minimum number of latency / dummy cycles required (RD_DUMMY_CTL.PRESENT2 > 0). For the Hyperbus protocol (DDR_CTL.SIZE3=7) at least 1 latency / dummy cycle has to be specified, for SPI with DQS capturing at least 2 latency / dummy cycles need to be selected (RD_DUMMY_CTL.SIZE5 > 0, exception see following note). - In case of falling edge RWDS / DQS capturing (CTL.CLOCK_IF_RX_SEL = '6') and SDR mode, SW should reduce the number of dummy cycles by 1 compared to the latency cycles required by the memory device. -DDR read commands need at least one dummy cycle -For Hyperbus, set RD DUMMY_CTL.SIZE5=initial latency cycles-2
      [4:0] SIZE5 — Number of dummy cycles (minus 1): '0': 1 cycles ... '31': 32 cycles. Note: this field specifies dummy cycles, not dummy Bytes!
    0x50 RD_DATA_CTL — Read data control
      fields as CORE[0].DEVICE[0].RD_ADDR_CTL
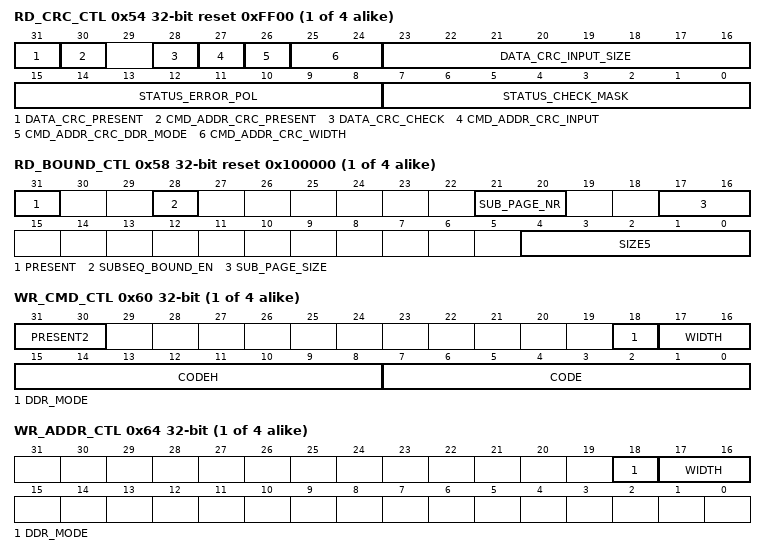
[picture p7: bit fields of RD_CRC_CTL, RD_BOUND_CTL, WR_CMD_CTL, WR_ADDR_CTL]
    0x54 RD_CRC_CTL reset 0xFF00 — Read Bus CRC control
      [31] DATA_CRC_PRESENT — Presence of data CRC field: '0': not present '1': present Note: Width and data transfer mode (SDR or DDR) of read data CRC fields are the same as for the associated read data fields, i.e. are specified by RD_DATA_CTL.WIDTH and RD_DATA_CTL.DDR_MODE.
      [30] CMD_ADDR_CRC_PRESENT — Presence of command / address CRC field: '0': not present '1': present Note: For octal data transfer with DDR mode (RD_CRC_CTL.WIDTH='3' and RD_CRC_CTL.DDR_MODE='1') the command / address CRC byte is sent twice, otherwise the command / address CRC byte is only sent once.
      [28] DATA_CRC_CHECK
      [27] CMD_ADDR_CRC_INPUT — Specifies which fields are included in the command / address CRC generation. '0': The command / address CRC field is generated over the address and (if present) mode fields only. '1': The command / address CRC field is generated over the command, address and (if present) mode fields.
      [26] CMD_ADDR_CRC_DDR_MODE — Mode of transfer rate of command / address CRC field.
      [25:24] CMD_ADDR_CRC_WIDTH — Width of command / address CRC field.
      [23:16] DATA_CRC_INPUT_SIZE — Number of input data bytes for CRC generation (minus 1), i.e. number of data bytes over which the data CRC field is generated (minus 1): '0': 1 byte ... '255': 256 bytes. Note: For octal data transfer with DDR mode (RD_DATA_CTL.WIDTH='3' and RD_DATA_CTL.DDR_MODE='1') the number of bytes for CRC generation must be even (i.e. DATA_CRC_INPUT_SIZE must be odd).
      [15:8] STATUS_ERROR_POL — Specifies the polarity of the Functional Safety Status field bits. There is 1 polarity bit for each Functional Safety Status bit. '0': The associated Functional Safety Status bit is active-low. '1': The associated Functional Safety Status bit is active-high.
      [7:0] STATUS_CHECK_MASK — Specifies which of the Functional Safety Status field bits are checked. There is 1 mask bit for each Functional Safety Status bit. '0': The associated Functional Safety Status bit is not checked. '1': The associated Functional Safety Status bit is checked. If the received Funciontal Safety Status bit = Functional Safety Status Error Polarity (STATUS_ERROR_POLARITY), then a Functional Safety Status error interrupt and a XIP bus error response is generated.
    0x58 RD_BOUND_CTL reset 0x100000 — Read boundary control
      [31] PRESENT — Presence of first page boundary latency cycles: '0': not present '1': present
      [28] SUBSEQ_BOUND_EN — Enable subsequent page boundary latency cycles. '0': Disabled. The page crossing latency cycles are only generated when crossing the first page boundary (i.e. the first time when the SUB_PAGE_NRth sub page boundary is crossed, e.g. with 2 sub pages per page when the 2nd sub page boundary is crossed). '1': Enabled. The page crossing latency cycles are generated when crossing the first and subsequent page boundaries (i.e. every time when a SUB_PAGE_NRth sub page boundary is crossed, e.g. with 2 sub pages per page when the 2nd, 4th, 6th, ... sub page boundary is crossed). Note: This only applies when the number of base latency cycles (SIZE5+1) is greater than the size of a page (base_latency > page_size). Must be set to 0 otherwise.
      [21:20] SUB_PAGE_NR — Specifies the number of sub pages per page. '0': 1 sub pages per page, i.e. page_size = sub_page_size '1': 2 sub pages per page, i.e. page_size = 2 x sub_page_size '2': 4 sub pages per page, i.e. page_size = 4 x sub_page_size '3': 8 sub pages per page, i.e. page_size = 8 x sub_page_size
      [17:16] SUB_PAGE_SIZE — Specifies the size of a memory sub page 'sub_page_size'. '0': sub_page_size = 8 words = 16 bytes (default). '1': sub_page_size = 16 words = 32 bytes. '2': sub_page_size = 32 words = 64 bytes. '3': sub_page_size = 64 words = 128 bytes.
      [4:0] SIZE5 — Number of base latency cycles (minus 1) used for calculating the number of fist page boundary crossing latency cycles: '0': base_latency = 1 cycles ... '31': base_latency = 32 cycles. The actual latency cycles when crossing the first page boundary depend on the start address of the transaction and is calculated as follows: if ((page_size - base_latency) < Start_Addr & (sub_page_size - 1)) { ((Start_Addr & (sub_page_size - 1)) - page_size + base_latency) } else { 0 }
    0x60 WR_CMD_CTL — Write command control
      [31:30] PRESENT2 — Presence of command field: '0': not present '1': present (1 Byte) '2': present (2 Byte for OPI) Note: For octal data transfer with DDR mode (WIDTH='3' and DDR_MODE='1') either the HB protocol needs to be selected (by ADDR_CTL.SIZE3='7') or this field needs to be set to PRESENT2='2'.
      [18] DDR_MODE — Mode of transfer rate.
      [17:16] WIDTH — Width of transfer.
      [15:8] CODEH — Command high byte code. This field specifies the most significant command byte, sent before the least significant command byte (CODE). It is only used when PRESENT2 = '2'.
      [7:0] CODE — Command byte code.
    0x64 WR_ADDR_CTL — Write address control
      fields as CORE[0].DEVICE[0].RD_ADDR_CTL
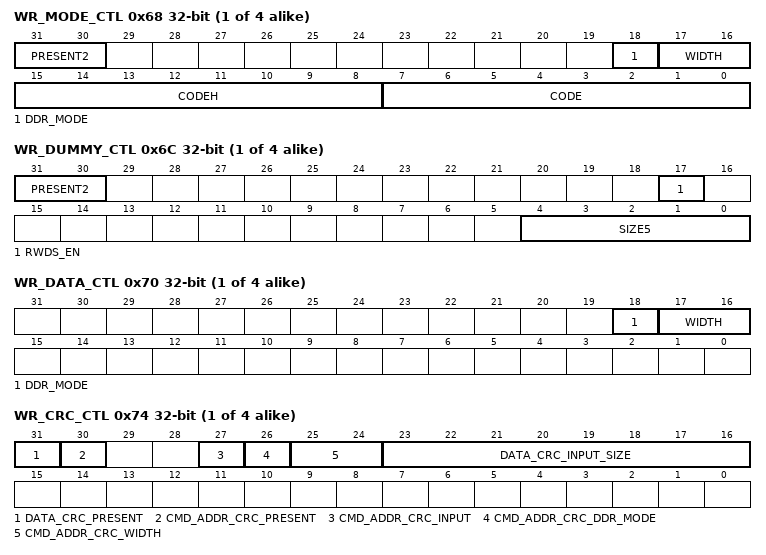
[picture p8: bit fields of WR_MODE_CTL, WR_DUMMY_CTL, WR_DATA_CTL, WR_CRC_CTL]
    0x68 WR_MODE_CTL — Write mode control
      [31:30] PRESENT2 — Presence of mode field: '0': not present '1': present (1 Byte) '2': present (2 Byte for OPI) Note: For octal data transfer with DDR mode (WIDTH='3' and DDR_MODE='1') this field needs to be set to PRESENT2='2' to generate a mode field (or to PRESENT2='0').
      [18] DDR_MODE — Mode of transfer rate.
      [17:16] WIDTH — Width of transfer.
      [15:8] CODEH — Mode high byte code. This field specifies the most significant mode byte, sent before the least significant mode byte (CODE). It is only used when PRESENT2 = '2'.
      [7:0] CODE — Mode byte code.
    0x6C WR_DUMMY_CTL — Write dummy control
      [31:30] PRESENT2 — Presence of dummy cycles: '0': not present '1': present '2': present - Dummy cycles are doubled when RWDS refresh indicator is high during CA cycle. (HyperRAM variable latency mode)
      [17] RWDS_EN — Read-Write-Data-Strobe Enable. Specifies whether the RWDS output signal should be driven starting in the last dummy cycle until DESELECT. This is needed for write transactions with byte masking via RWDS (e.g. Hyperbus). '0': do not drive RWDS output '1': drive RWDS output starting in last dummy cycle until DESELECT Note: this field is located in the WR_DUMMY_CTL register (and not in the WR_DATA_CTL register) since the RWDS signal needs to be driven already in the last dummy cycle.
      [4:0] SIZE5 — Number of dummy cycles (minus 1): '0': 1 cycles ... '31': 32 cycles.
    0x70 WR_DATA_CTL — Write data control
      fields as CORE[0].DEVICE[0].RD_ADDR_CTL
    0x74 WR_CRC_CTL — Write Bus CRC control
      [31] DATA_CRC_PRESENT — Presence of data CRC field: '0': not present '1': present Note: Width and data transfer mode (SDR or DDR) of read data CRC fields are the same as for the associated read data fields, i.e. are specified by RD_DATA_CTL.WIDTH and RD_DATA_CTL.DDR_MODE. Note: For octal data transfer with DDR mode (RD_DATA_CTL.WIDTH='3' and RD_DATA_CTL.DDR_MODE='1') the data CRC byte is sent twice, otherwise the data CRC byte is only sent once.
      [30] CMD_ADDR_CRC_PRESENT — Presence of command / address CRC field: '0': not present '1': present Note: For octal data transfer with DDR mode (RD_CRC_CTL.WIDTH='3' and RD_CRC_CTL.DDR_MODE='1') the command / address CRC byte is sent twice, otherwise the command / address CRC byte is only sent once.
      [27] CMD_ADDR_CRC_INPUT — Specifies which fields are included in the command / address CRC generation. '0': The command / address CRC field is generated over the address and (if present) mode fields only. '1': The command / address CRC field is generated over the command, address and (if present) mode fields.
      [26] CMD_ADDR_CRC_DDR_MODE — Mode of transfer rate of command / address CRC field.
      [25:24] CMD_ADDR_CRC_WIDTH — Width of command / address CRC field.
      [23:16] DATA_CRC_INPUT_SIZE — Number of input data bytes for CRC generation (minus 1), i.e. number of data bytes over which the data CRC field is generated (minus 1): '0': 1 byte ... '255': 256 bytes. Note: For octal data transfer with DDR mode (WR_DATA_CTL.WIDTH='3' and WR_DATA_CTL.DDR_MODE='1') the number of bytes for CRC generation must be even (i.e. DATA_CRC_INPUT_SIZE must be odd).

## Notices in the file
Copyright 2016-2019, Cypress Semiconductor Corporation.  All rights reserved.
You may use this file only in accordance with the license, terms, conditions,
disclaimers, and limitations in the end user license agreement accompanying
the software package with which this file was provided.
